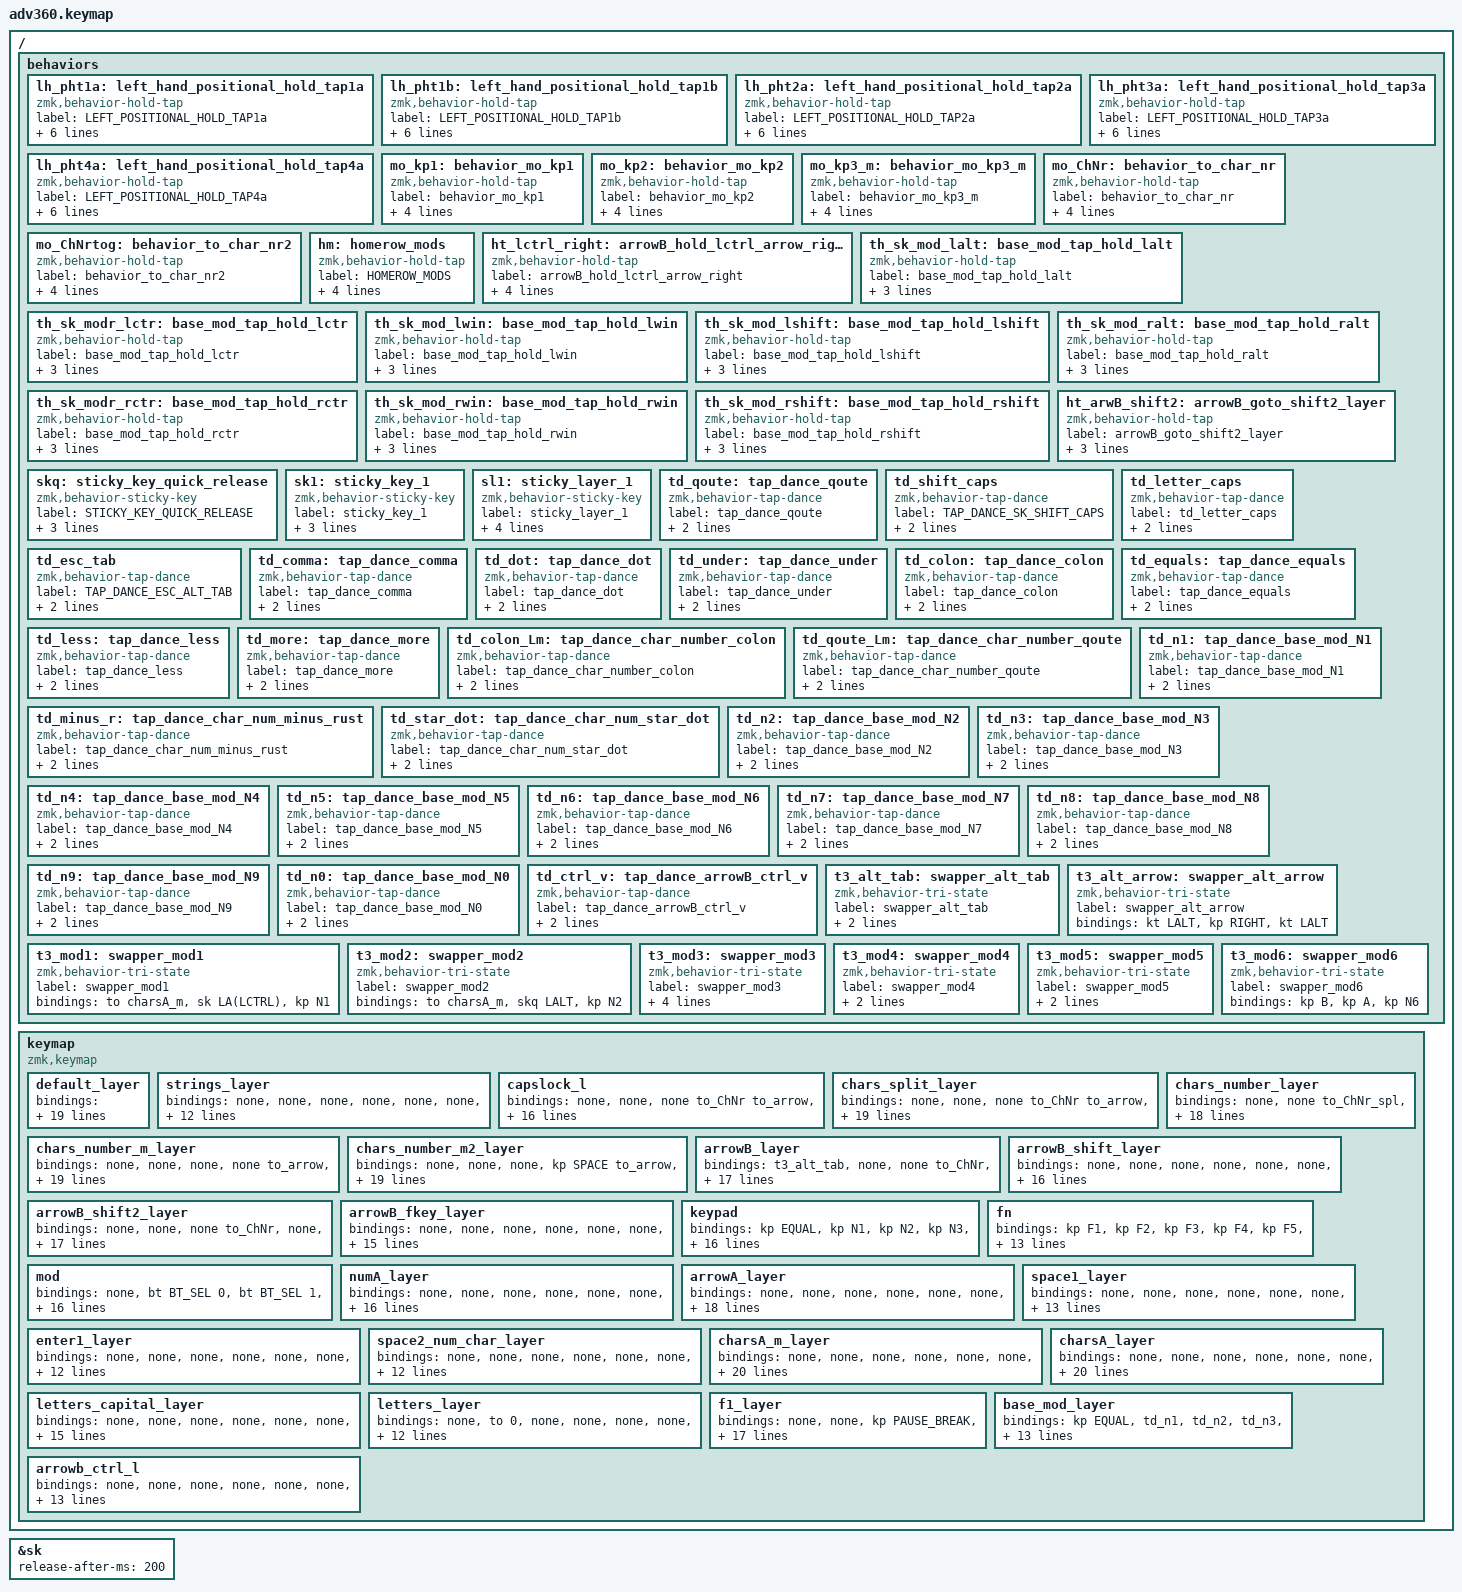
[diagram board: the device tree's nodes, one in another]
#include <behaviors.dtsi>
#include <dt-bindings/zmk/keys.h>
#include <dt-bindings/zmk/bt.h>
#include <dt-bindings/zmk/rgb.h>
#include <dt-bindings/zmk/backlight.h>

#define DEFAULT           0
#define strings_l         1
#define capslock_l          2
#define chars_split       3
#define chars_number      4
#define chars_number_m    5
#define chars_number_m2   6
#define arrowB            7
#define arrowB_shift      8  //|=
#define arrowB_shift2     9
#define arrowB_fkey       10

#define keypad_l          11 //default
#define fn_l              12 //default
#define mod_l             13 //default

#define numA              14
#define arrowA            15
#define space1            16
#define enter1            17
#define space2_num_char   18
#define charsA_m          19
#define charsA            20
#define letters_cap       21
#define letters           22
#define f1_layer          23
#define base_mod          24
#define arrowb_ctrl_l     25


//#define LSW LS(LWIN)

  &sk {
     release-after-ms = <200>;
 };

/ {
    behaviors {
      #include "macros.dtsi"

      lh_pht1a: left_hand_positional_hold_tap1a {
            compatible = "zmk,behavior-hold-tap";
            label = "LEFT_POSITIONAL_HOLD_TAP1a";
            #binding-cells = <2>;
  //          flavor = "tap-unless-interrupted";
            flavor = "tap-preferred";
            tapping-term-ms = <200>;                        // <---[[produces tap if held longer than tapping-term-ms]]
            quick-tap-ms = <200>;
            //global-quick-tap;
            bindings = <&kp>, <&kp>;
                                        //6              y               h                n
            hold-trigger-key-positions = <8 9 10 11 12   22 23 24 25 26  40 41 42 43 44   60 61 62 63 64>;    // 14 <---[[right-hand keys]]
      };

      lh_pht1b: left_hand_positional_hold_tap1b {
            compatible = "zmk,behavior-hold-tap";
            label = "LEFT_POSITIONAL_HOLD_TAP1b";
            #binding-cells = <2>;
   //         flavor = "tap-unless-interrupted";
            flavor = "tap-preferred";
            tapping-term-ms = <200>;                        // <---[[produces tap if held longer than tapping-term-ms]]
            quick-tap-ms = <200>;
            //global-quick-tap;
            bindings = <&kp>, <&kp>;
                                        //1              q               a                z
            hold-trigger-key-positions = <1 2 3 4 5      15 16 17 18 19  29 30 31 32 33   47 48 49 50 51>;    // 14 <---[[right-hand keys]]
      };


      lh_pht2a: left_hand_positional_hold_tap2a {
            compatible = "zmk,behavior-hold-tap";
            label = "LEFT_POSITIONAL_HOLD_TAP2a";
            #binding-cells = <2>;
            flavor = "tap-preferred";
            tapping-term-ms = <1000>;                        // <---[[produces tap if held longer than tapping-term-ms]]
            quick-tap-ms = <2000>;
            //global-quick-tap;
            bindings = <&kp>, <&kp>;
            hold-trigger-key-positions = <8 9 10 11 12   22 23 24 25 26  40 41 42 43 44   60 61 62 63 64>;    // 14 <---[[right-hand keys]]
      };

      lh_pht3a: left_hand_positional_hold_tap3a {
            compatible = "zmk,behavior-hold-tap";
            label = "LEFT_POSITIONAL_HOLD_TAP3a";
            #binding-cells = <2>;
            flavor = "balanced";
            tapping-term-ms = <1000>;                        // <---[[produces tap if held longer than tapping-term-ms]]
            quick-tap-ms = <2000>;
            //global-quick-tap;
            bindings = <&kp>, <&kp>;
            hold-trigger-key-positions = <8 9 10 11 12   22 23 24 25 26  40 41 42 43 44   60 61 62 63 64>;    // 14 <---[[right-hand keys]]
      };

      lh_pht4a: left_hand_positional_hold_tap4a {
            compatible = "zmk,behavior-hold-tap";
            label = "LEFT_POSITIONAL_HOLD_TAP4a";
            #binding-cells = <2>;
            flavor = "tap-unless-interrupted";
            tapping-term-ms = <400>;                        // <---[[produces tap if held longer than tapping-term-ms]]
            quick-tap-ms = <200>;
            //global-quick-tap;
            bindings = <&kp>, <&kp>;
            hold-trigger-key-positions = <8 9 10 11 12   22 23 24 25 26  40 41 42 43 44   60 61 62 63 64>;    // 14 <---[[right-hand keys]]
      };
// --------------------------------------------------------
    mo_kp1: behavior_mo_kp1 {
       label = "behavior_mo_kp1";
       compatible = "zmk,behavior-hold-tap";
       #binding-cells = <2>;
       flavor = "tap-preferred";
       tapping-term-ms = <200>;
       quick-tap-ms = <200>;
       bindings = <&mo>, <&kp>;
    };

    mo_kp2: behavior_mo_kp2 {
       label = "behavior_mo_kp2";
       compatible = "zmk,behavior-hold-tap";
       #binding-cells = <2>;
       flavor = "tap-preferred";
       tapping-term-ms = <200>;
       quick-tap-ms = <200>;
       bindings = <&mo>, <&kp>;
    }; 

    mo_kp3_m: behavior_mo_kp3_m {
       label = "behavior_mo_kp3_m";
       compatible = "zmk,behavior-hold-tap";
       #binding-cells = <2>;
       flavor = "tap-preferred";
       tapping-term-ms = <200>;
       quick-tap-ms = <200>;
       bindings = <&mo>, <&m_to0_space>;
    };

    mo_ChNr: behavior_to_char_nr {
       label = "behavior_to_char_nr";
       compatible = "zmk,behavior-hold-tap";
       #binding-cells = <2>;
       flavor = "tap-preferred";
       tapping-term-ms = <200>;
       quick-tap-ms = <200>;
       bindings = <&mo>, <&kp>;
    }; 

    mo_ChNrtog: behavior_to_char_nr2 {
       label = "behavior_to_char_nr2";
       compatible = "zmk,behavior-hold-tap";
       #binding-cells = <2>;
       flavor = "tap-preferred";
       tapping-term-ms = <200>;
       quick-tap-ms = <200>;
       bindings = <&tog>, <&kp>;
    }; 

// --------------------------------------------------------
      hm: homerow_mods {
          compatible = "zmk,behavior-hold-tap";
          label = "HOMEROW_MODS";
          #binding-cells = <2>;
          tapping-term-ms = <200>;
          quick_tap_ms = <175>;
          flavor = "tap-preferred";
          bindings = <&kp>, <&kp>;
      };

// --------------------------------------------------------
// TODO: ARROW_MODS
// not used

  ht_lctrl_right: arrowB_hold_lctrl_arrow_right {
            label = "arrowB_hold_lctrl_arrow_right";
            compatible = "zmk,behavior-hold-tap";
            #binding-cells = <2>;
            flavor = "tap-preferred";
            tapping-term-ms = <200>;                        // <---[[produces tap if held longer than tapping-term-ms]]
            quick-tap-ms = <200>;
            //global-quick-tap;
           // bindings = <&m_lctrl_right>, <&kp RIGHT>;       // TODO: ARROW_MODS
             bindings = <&mo>, <&kp>;
                                        //1              q               a                z
           // hold-trigger-key-positions = <1 2 3 4 5      15 16 17 18 19  29 30 31 32 33   47 48 49 50 51>;    // 14 <---[[right-hand keys]]
      };

// --------------------------------------------------------
// used for modifirs on base layer
// you still have the convenience of a sticky key, you don't have to keep pressing the key to activate it
// if you press it it activates the mod, and takes you to new layer where you can use top row for numbers

   th_sk_mod_lalt: base_mod_tap_hold_lalt {
            label = "base_mod_tap_hold_lalt";
            compatible = "zmk,behavior-hold-tap";
            #binding-cells = <2>;
            flavor = "hold-preferred";
            tapping-term-ms = <200>;
            bindings = <&m_0mod_lalt>, <&skq>;
        };

    th_sk_modr_lctr: base_mod_tap_hold_lctr {
            label = "base_mod_tap_hold_lctr";
            compatible = "zmk,behavior-hold-tap";
            #binding-cells = <2>;
            flavor = "hold-preferred";
            tapping-term-ms = <200>;
            bindings = <&m_0mod_lctr>, <&skq>;
        };

   th_sk_mod_lwin: base_mod_tap_hold_lwin {
            label = "base_mod_tap_hold_lwin";
            compatible = "zmk,behavior-hold-tap";
            #binding-cells = <2>;
            flavor = "hold-preferred";
            tapping-term-ms = <200>;
            bindings = <&m_0mod_lwin>, <&skq>;
        };

   th_sk_mod_lshift: base_mod_tap_hold_lshift {
            label = "base_mod_tap_hold_lshift";
            compatible = "zmk,behavior-hold-tap";
            #binding-cells = <2>;
            flavor = "hold-preferred";
            tapping-term-ms = <200>;
            bindings = <&m_0mod_lshift>, <&skq>;
        };

//------

   th_sk_mod_ralt: base_mod_tap_hold_ralt {
            label = "base_mod_tap_hold_ralt";
            compatible = "zmk,behavior-hold-tap";
            #binding-cells = <2>;
            flavor = "hold-preferred";
            tapping-term-ms = <200>;
            bindings = <&m_0mod_ralt>, <&skq>;
        };

    th_sk_modr_rctr: base_mod_tap_hold_rctr {
            label = "base_mod_tap_hold_rctr";
            compatible = "zmk,behavior-hold-tap";
            #binding-cells = <2>;
            flavor = "hold-preferred";
            tapping-term-ms = <200>;
            bindings = <&m_0mod_rctr>, <&skq>;
        };

   th_sk_mod_rwin: base_mod_tap_hold_rwin {
            label = "base_mod_tap_hold_rwin";
            compatible = "zmk,behavior-hold-tap";
            #binding-cells = <2>;
            flavor = "hold-preferred";
            tapping-term-ms = <200>;
            bindings = <&m_0mod_rwin>, <&skq>;
        };

   th_sk_mod_rshift: base_mod_tap_hold_rshift {
            label = "base_mod_tap_hold_rshift";
            compatible = "zmk,behavior-hold-tap";
            #binding-cells = <2>;
            flavor = "hold-preferred";
            tapping-term-ms = <200>;
            bindings = <&m_0mod_rshift>, <&skq>;
        };


// --------------------------------------------------------
// arrowB_layer
// 

   ht_arwB_shift2: arrowB_goto_shift2_layer {
            label = "arrowB_goto_shift2_layer";
            compatible = "zmk,behavior-hold-tap";
            #binding-cells = <2>;
            flavor = "hold-preferred";
            tapping-term-ms = <200>;
            bindings = <&mo>, <&to>;
        };

// --------------------------------------------------------


      skq: sticky_key_quick_release {
        compatible = "zmk,behavior-sticky-key";
        label = "STICKY_KEY_QUICK_RELEASE";
        #binding-cells = <1>;
        bindings = <&kp>;
        release-after-ms = <400>;
        quick-release;
      };

    sk1: sticky_key_1 {
        compatible = "zmk,behavior-sticky-key";
        label = "sticky_key_1";
        #binding-cells = <1>;
        release-after-ms = <1000>;
        bindings = <&kp>;
        ignore-modifiers;
    };

    sl1: sticky_layer_1 {
        compatible = "zmk,behavior-sticky-key";
        label = "sticky_layer_1";
        #binding-cells = <1>;
        release-after-ms = <1000>;
        bindings = <&mo>;
        ignore-modifiers;
        quick-release;
    };


// --------------------------------------------------------

   td_qoute: tap_dance_qoute {
            compatible = "zmk,behavior-tap-dance";
            label = "tap_dance_qoute";
            #binding-cells = <0>;
            tapping-term-ms = <200>;
            bindings = <&kp SINGLE_QUOTE>, <&kp DOUBLE_QUOTES>;
        };

   td_shift_caps: td_shift_caps {
            compatible = "zmk,behavior-tap-dance";
            label = "TAP_DANCE_SK_SHIFT_CAPS";
            #binding-cells = <0>;
            tapping-term-ms = <200>;
            bindings = <&skq LSHFT>, <&to capslock_l>;
      };

   td_letter_caps: td_letter_caps {
            compatible = "zmk,behavior-tap-dance";
            label = "td_letter_caps";
            #binding-cells = <0>;
            tapping-term-ms = <200>;
            bindings = <&sl letters_cap>, <&to capslock_l>;
      };

      td_esc_tab: td_esc_tab {
            compatible = "zmk,behavior-tap-dance";
            label = "TAP_DANCE_ESC_ALT_TAB";
            #binding-cells = <0>;
            tapping-term-ms = <200>;
            bindings = <&kp ESC>, <&kp LA(TAB)>;
      };

     td_comma: tap_dance_comma {
            compatible = "zmk,behavior-tap-dance";
            label = "tap_dance_comma";
            #binding-cells = <0>;
            tapping-term-ms = <200>;
            bindings = <&kp COMMA>, <&kp LESS_THAN>;
        };
 
    td_dot: tap_dance_dot {
            compatible = "zmk,behavior-tap-dance";
            label = "tap_dance_dot";
            #binding-cells = <0>;
            tapping-term-ms = <200>;
            bindings = <&kp DOT>, <&kp GREATER_THAN>;
        };

    td_under: tap_dance_under {
            compatible = "zmk,behavior-tap-dance";
            label = "tap_dance_under";
            #binding-cells = <0>;
            tapping-term-ms = <200>;
            bindings = <&kp UNDER>, <&kp QMARK>;
        }; 

    td_colon: tap_dance_colon {
            compatible = "zmk,behavior-tap-dance";
            label = "tap_dance_colon";
            #binding-cells = <0>;
            tapping-term-ms = <200>;
            bindings = <&kp SEMI>, <&kp COLON>;
        }; 

// -----------
// use on chars_number_m_layer

    td_equals: tap_dance_equals {
            compatible = "zmk,behavior-tap-dance";
            label = "tap_dance_equals";
            #binding-cells = <0>;
            tapping-term-ms = <200>;
            bindings = <&m_toNrCh_equal>, <&m_toNrCh_equal2>;
        }; 

    td_less: tap_dance_less {
            compatible = "zmk,behavior-tap-dance";
            label = "tap_dance_less";
            #binding-cells = <0>;
            tapping-term-ms = <200>;
            bindings = <&m_toNrCh_less>, <&m_toNrCh_less2>;
        }; 

    td_more: tap_dance_more {
            compatible = "zmk,behavior-tap-dance";
            label = "tap_dance_more";
            #binding-cells = <0>;
            tapping-term-ms = <200>;
            bindings = <&m_toNrCh_more>, <&m_toNrCh_more2>;
        }; 


    td_colon_Lm: tap_dance_char_number_colon {
            label = "tap_dance_char_number_colon";
            compatible = "zmk,behavior-tap-dance";
            #binding-cells = <0>;
            tapping-term-ms = <200>;
            bindings = <&m_toNrCh_colon>, <&m_toNrCh_colon2>;
        }; 

td_qoute_Lm: tap_dance_char_number_qoute {
            label = "tap_dance_char_number_qoute";
            compatible = "zmk,behavior-tap-dance";
            #binding-cells = <0>;
            tapping-term-ms = <200>;
            bindings = <&m_toNrCh_qoute>, <&m_toNrCh_qoute2>;
        }; 

    td_minus_r: tap_dance_char_num_minus_rust {
            label = "tap_dance_char_num_minus_rust";
            compatible = "zmk,behavior-tap-dance";
            #binding-cells = <0>;
            tapping-term-ms = <200>;
            bindings = <&m_toNrCh_minus>, <&m_toNrCh_r_minus>;
        }; 

    td_star_dot: tap_dance_char_num_star_dot {
            label = "tap_dance_char_num_star_dot";
            compatible = "zmk,behavior-tap-dance";
            #binding-cells = <0>;
            tapping-term-ms = <200>;
            bindings = <&m_toNrCh_star>, <&m_toNrCh_star2>;
        }; 


// --------------------------------------------------------

   td_n1: tap_dance_base_mod_N1 {
            label = "tap_dance_base_mod_N1";
            compatible = "zmk,behavior-tap-dance";
            #binding-cells = <0>;
            tapping-term-ms = <200>;
            bindings = <&kp N1>, <&kp N6>;
        };

   td_n2: tap_dance_base_mod_N2 {
            label = "tap_dance_base_mod_N2";
            compatible = "zmk,behavior-tap-dance";
            #binding-cells = <0>;
            tapping-term-ms = <200>;
            bindings = <&kp N2>, <&kp N7>;
        };

   td_n3: tap_dance_base_mod_N3 {
            label = "tap_dance_base_mod_N3";
            compatible = "zmk,behavior-tap-dance";
            #binding-cells = <0>;
            tapping-term-ms = <200>;
            bindings = <&kp N3>, <&kp N8>;
        };

   td_n4: tap_dance_base_mod_N4 {
            label = "tap_dance_base_mod_N4";
            compatible = "zmk,behavior-tap-dance";
            #binding-cells = <0>;
            tapping-term-ms = <200>;
            bindings = <&kp N4>, <&kp N9>;
        };

   td_n5: tap_dance_base_mod_N5 {
            label = "tap_dance_base_mod_N5";
            compatible = "zmk,behavior-tap-dance";
            #binding-cells = <0>;
            tapping-term-ms = <200>;
            bindings = <&kp N5>, <&kp N0>;
        };

   td_n6: tap_dance_base_mod_N6 {
            label = "tap_dance_base_mod_N6";
            compatible = "zmk,behavior-tap-dance";
            #binding-cells = <0>;
            tapping-term-ms = <200>;
            bindings = <&kp N6>, <&kp N1>;
        };

   td_n7: tap_dance_base_mod_N7 {
            label = "tap_dance_base_mod_N7";
            compatible = "zmk,behavior-tap-dance";
            #binding-cells = <0>;
            tapping-term-ms = <200>;
            bindings = <&kp N7>, <&kp N2>;
        };

   td_n8: tap_dance_base_mod_N8 {
            label = "tap_dance_base_mod_N8";
            compatible = "zmk,behavior-tap-dance";
            #binding-cells = <0>;
            tapping-term-ms = <200>;
            bindings = <&kp N8>, <&kp N3>;
        };

   td_n9: tap_dance_base_mod_N9 {
            label = "tap_dance_base_mod_N9";
            compatible = "zmk,behavior-tap-dance";
            #binding-cells = <0>;
            tapping-term-ms = <200>;
            bindings = <&kp N9>, <&kp N4>;
        };

   td_n0: tap_dance_base_mod_N0 {
            label = "tap_dance_base_mod_N0";
            compatible = "zmk,behavior-tap-dance";
            #binding-cells = <0>;
            tapping-term-ms = <200>;
            bindings = <&kp N0>, <&kp N5>;
        };

// --------------------------------------------------------
// used on arrowB_layer

   td_ctrl_v: tap_dance_arrowB_ctrl_v {
            label = "tap_dance_arrowB_ctrl_v";
            compatible = "zmk,behavior-tap-dance";
            #binding-cells = <0>;
            tapping-term-ms = <200>;
            bindings = <&kp LC(V)>, <&a_ctrl_v_enter>;
        };

// --------------------------------------------------------

// window switching in windows
  t3_alt_tab: swapper_alt_tab {
            compatible = "zmk,behavior-tri-state";
            label = "swapper_alt_tab";
            #binding-cells = <0>;
            bindings = <&kt LALT>, <&kp TAB>, <&kt LALT>;
            ignored-key-positions = <46 65>;  // left shfit and right shift
        };

// you can use this to move the currsor forward and using a single key only
// its kind of similar how the sticky key works, as long as you keep pressing it
// it will output the alt+arrow key and it is disabled by any other key
// "smart" key combination

  t3_alt_arrow: swapper_alt_arrow {
            label = "swapper_alt_arrow";
            compatible = "zmk,behavior-tri-state";
            #binding-cells = <0>;
            bindings = <&kt LALT>, <&kp RIGHT>, <&kt LALT>;
           // ignored-key-positions = <46 65>;  // left shfit and right shift
        };

  t3_mod1: swapper_mod1 {
            label = "swapper_mod1";
            compatible = "zmk,behavior-tri-state";
            #binding-cells = <0>;
            bindings = <&to charsA_m>, <&sk LA(LCTRL)>, <&kp N1>;
           // ignored-key-positions = <46 65>;  // left shfit and right shift
        };

  t3_mod2: swapper_mod2 {
            label = "swapper_mod2";
            compatible = "zmk,behavior-tri-state";
            #binding-cells = <0>;
            bindings = <&to charsA_m>, <&skq LALT>, <&kp N2>;
           // ignored-key-positions = <46 65>;  // left shfit and right shift
        };

  t3_mod3: swapper_mod3 {
            label = "swapper_mod3";
            compatible = "zmk,behavior-tri-state";
            #binding-cells = <0>;
            bindings = <&to charsA>, <&sk LA(LSHFT)>, <&kp N3>;
            ignored-key-positions = <8 9 10 11 12   22 23 24 25 26  40 41 42 43 44   60 61 62 63 64>;
            ignored-layers = <0 charsA_m charsA>;
        };

  t3_mod4: swapper_mod4 {
            label = "swapper_mod4";
            compatible = "zmk,behavior-tri-state";
            #binding-cells = <0>;
            //bindings = <&skq LALT>, <&sl charsA>, <&kp N4>;         //this combination doesn't work;
            bindings = <&none>, <&sl charsA>, <&sk LA(LSHFT)>;
           // ignored-key-positions = <46 65>;  
            ignored-layers = <charsA>;
        };

  t3_mod5: swapper_mod5 {
            label = "swapper_mod5";
            compatible = "zmk,behavior-tri-state";
            #binding-cells = <0>;
            bindings = <&to charsA>, <&kp A>, <&kp N5>;
           // ignored-key-positions = <46 65>;  // left shfit and right shift
            ignored-layers = <charsA>;
        };

    t3_mod6: swapper_mod6 {
            label = "swapper_mod6";
            compatible = "zmk,behavior-tri-state";
            #binding-cells = <0>;
            bindings = <&kp B>, <&kp A>, <&kp N6>;
           // ignored-key-positions = <46 65>;  // left shfit and right shift
        };


// --------------------------------------------------------


};



  keymap {
    compatible = "zmk,keymap";

//    #define hr_A &lh_pht1 LSFT A
//    #define hr_S &lh_pht2 LWIN S
//    #define hr_D &lh_pht3 LCTRL D
 //   #define hr_F &lh_pht4 LALT F

 //   #define hr_A &lh_pht1 LSFT A
 //   #define hr_S &lh_pht2 LSFT S
 //   #define hr_D &lh_pht3 LSFT D
 //   #define hr_F &lh_pht4 LSFT F

#define hr_A &lh_pht1a LSFT A
#define hr_S &lh_pht1a LSFT S
#define hr_D &lh_pht1a LSFT D
//#define hr_F &lh_pht1a LSFT F

#define hr_N1 &lh_pht1a LSFT N1
#define hr_N2 &lh_pht1a LSFT N2
#define hr_N3 &lh_pht1a LSFT N3
#define hr_N4 &lh_pht1a LSFT N4
#define hr_N5 &lh_pht1a LSFT N5

#define hr_Q &lh_pht1a LSFT Q
#define hr_W &lh_pht1a LSFT W
//#define hr_E &lh_pht1a LSFT E
#define hr_R &lh_pht1a LSFT R
#define hr_T &lh_pht1a LSFT T

#define hr_G &lh_pht1a LSFT G
#define hr_Z &lh_pht1a LSFT Z
#define hr_X &lh_pht1a LSFT X
#define hr_C &lh_pht1a LSFT C
#define hr_V &lh_pht1a LSFT V
#define hr_B &lh_pht1a LSFT B

 // ------

#define hr_Y &lh_pht1b LSFT Y
#define hr_U &lh_pht1b LSFT U
//#define hr_I &lh_pht1b LSFT I
#define hr_O &lh_pht1b LSFT O
#define hr_P &lh_pht1b LSFT P

#define hr_H &lh_pht1b LSFT H
#define hr_J &lh_pht1b LSFT J
#define hr_K &lh_pht1b LSFT K
//#define hr_L &lh_pht1b LSFT L
#define hr_COLON  &lh_pht1b LSFT COLON

#define hr_N6 &lh_pht1b LSFT N6
#define hr_N7 &lh_pht1b LSFT N7
//#define hr_N8 &lh_pht1b LSFT N8
#define hr_N9 &lh_pht1b LSFT N9
#define hr_N0 &lh_pht1b LSFT N0

#define hr_N &lh_pht1b LSFT N
#define hr_M &lh_pht1b LSFT M
#define hr_COMMA &lh_pht1b LSFT COMMA
#define hr_DOT &lh_pht1b LSFT DOT
//#define hr_FSLH &lh_pht1b LSFT FSLH
#define hr_UNDER &lh_pht1b LSFT UNDER

#define mo_SPACE &mo_kp1 space1 SPACE
#define mo_ENTER &mo_kp1 enter1 ENTER

//on the char_num layer allows to press enter and move to L0
#define mo_SPACE2   &mo_kp1   space2_num_char SPACE
// macron on tap, on hold enable new layer
// allows to tap and change layer, on hold on the new layer you can change layer as well
#define mo_SPACE3_m &mo_kp3_m space2_num_char 0


//#define mo_FF1 &mo_kp2 charsA F
//#define mo_FF2 &mo_kp2 arrowA F
//#define mo_FF2 &mo_kp2 arrowB_shift2 F
#define mo_FF2 &mo_kp2 arrowB_fkey F

//#define mo_N4 &mo_kp2 arrowA N4
#define mo_N4 &mo_kp2 arrowB_fkey N4

//string shortcuts
#define mo_E &mo_kp2 strings_l E
#define mo_I &mo_kp2 strings_l I


//#define mo_DD &mo_kp2 charsA D    
#define   mo_DD &mo_ChNr     chars_number_m D  
//#define mo_KK &mo_kp2 numA K
#define   mo_KK &mo_ChNr     chars_number_m K     


//#define mo_SS &mo_ChNrtog  chars_number_m S
#define   mo_SS &mo_ChNr     chars_number_m2 S
#define   mo_LL &mo_ChNr     chars_number_m2 L


//allows to type: \n or \d
// space, enter + alt combination
#define mo_N5    &mo_ChNr     chars_number_m N5
#define mo_SLASH &mo_ChNr     chars_number_m SLASH

// space, enter + ctrl combination
#define mo_N6    &mo_ChNr     chars_number_m2 N6
#define mo_PLUS  &mo_ChNr     chars_number_m2 PLUS


#define to_arrow &to arrowB 

#define to_ChNr     &to chars_number 
#define to_ChNr_spl &to chars_split 



// --------------------------------------------------------

#define _lalt  &th_sk_mod_lalt 0 LALT 
#define _lctr  &th_sk_modr_lctr 0 LCTRL
#define _lwin  &th_sk_mod_lwin 0 LWIN
#define _lsft  &th_sk_mod_lshift 0 LSHFT 

#define _ralt  &th_sk_mod_ralt 0 RALT 
#define _rctr  &th_sk_modr_rctr 0 RCTRL
#define _rwin  &th_sk_mod_rwin 0 RWIN
#define _rsft  &th_sk_mod_rshift 0 RSHFT 

// --------------------------------------------------------

#define go_arrowB_shift2 &ht_arwB_shift2 arrowB_shift2 arrowB_shift2

// --------------------------------------------------------

    default_layer {
      bindings = <
       &t3_alt_tab  hr_N1     to_ChNr_spl to_ChNr   to_arrow    hr_N5  &tog keypad_l                                                                                   &mo mod_l   hr_N6  hr_N7       to_ChNr    to_ChNr_spl hr_N0      &kp BSPC
       &td_esc_tab  hr_Q       hr_W       mo_E      hr_R        hr_T   &t3_alt_arrow                                                                                   &none       hr_Y   hr_U         mo_I       hr_O       hr_P       &kp DEL
       &kp  TAB     hr_A       mo_SS      mo_DD     mo_FF2      hr_G   &kp LC(RIGHT)               &kp ENTER  &bootloader                &bootloader  &kp Z            &none       hr_H   hr_J         mo_KK      mo_LL      hr_COLON   &kp DOUBLE_QUOTES
    &td_shift_caps  hr_Z       hr_X       hr_C      hr_V        hr_B                    &none      &none      &kp BSPC    &none   &none  &kp PG_UP &none     &none                 hr_N   hr_M         hr_COMMA   hr_DOT     hr_UNDER   _rsft
       &mo  2       _lwin      _lctr      _lalt     &sl arrowA                        mo_SPACE   &sl charsA   &kp DEL                    &kp PG_DN &sl numA  mo_ENTER                     &sl f1_layer _ralt      _rctr      _rwin      &mo 2
      >; 
    };

// h  : https://
// d  : doesn't
// c  : can't 

    strings_layer {
      bindings = <
        &none &none        &none        &none        &none        &none        &none                                                                              &none      &none        &none        &none        &none        &none        &none
        &none &to 0        &none        &none        &none        &none        &none                                                                              &none      &none        &none        &none        &none        &none        &none
        &none &none        &m_s_self    &m_d_doesnt  &none        &none        &none            &none  &none                        &none   &kp S                 &none      &m_h_https   &none        &none        &none        &none        &none
        &none &none        &none        &m_c_cant    &none        &none                 &none   &none  &none  &none         &none   &none   &none  &none                     &none        &none        &none        &none        &none        &none
        &none &none        &none        &none        &none                              &none   &none  &none                        &none   &none  &none                                  &none        &none        &none        &none        &none
      >;
    };

    capslock_l {
      bindings = <
        &none &none        &none        to_ChNr      to_arrow     &none        &none                                                                               &none      &none        &none        to_ChNr_spl   &none        &none           &kp BSPC
        &none &kp LS(Q)    &kp LS(W)    &kp LS(E)    &kp LS(R)    &kp LS(T)    &none                                                                               &none      &kp LS(Y)    &kp LS(U)    &kp LS(I)     &kp LS(O)    &kp LS(P)       &kp DEL
      &kp TAB &kp LS(A)    &kp LS(S)    &kp LS(D)    &kp LS(F)    &kp LS(G)    &none               &none       &none                        &none    &kp U         &none      &kp LS(H)    &kp LS(J)    &kp LS(K)     &kp LS(L)    &kp COLON       &kp DOUBLE_QUOTES
        &to 0 &kp LS(Z)    &kp LS(X)    &kp LS(C)    &kp LS(V)    &kp LS(B)             &none      &none       &none  &none         &none   &none    &none  &none             &kp LS(N)    &kp LS(M)    &kp COMMA     &kp DOT      &kp UNDER       &none
        &none &none        &none        &none        mo_SPACE2                         mo_SPACE3_m &sl charsA  &none                &none   &sl numA &m_to0_enter             &kp ENTER    &none         &none        &none           &none
      >;
    };

// &m_to0_space

// chars are on the left and right half
// the hard to reach chars from the left has been moved to right
// some combination so chars should be easier to type right now
// the righ side keys are kept "fixed" of what we already use, so you only have to learn the keys on the left
//
// - Lshift on double tap enables capslock layer
// - moved double_qoutes to index finger to make it easy to type: { "%p" }
// layer used to type "wired" char sequences that are "unergonomic" otherwise
// \= @tile
// "#{@item.type}
// - typing '.*' requires right hand to jump from the bottom to top row; added the '*' char in the "alt" key spot

    chars_split_layer {
      bindings = <
        &none            &none       &none          to_ChNr           to_arrow       &none             &none                                                                               &none       &none      &none            to_ChNr       &none     &none       &kp BSPC
        &none            &kp QMARK   &kp GRAVE      &kp BACKSLASH     &kp PERCENT    &kp RIGHT_BRACKET &none                                                                               &none       &kp AT     &kp LEFT_BRACKET &kp MINUS     &kp EQUAL &kp EXCL    &kp DEL
        &kp SINGLE_QUOTE &kp STAR    &kp AMPERSAND  &kp TILDE         &kp LEFT_BRACE &kp RIGHT_BRACE   &sl letters         &kp ENTER    &none                 &none  &kp T                 &sl letters &kp DOLLAR &kp LPAR         mo_SLASH      mo_PLUS   &kp COLON   &kp DOUBLE_QUOTES
        &to capslock_l   &kp SEMI    &kp LESS_THAN  &kp GREATER_THAN  &kp CARET      &kp RPAR                      &none   &none        &none  &none  &none   &none  &none   &none                     &kp PIPE   &kp HASH         &kp COMMA     &kp DOT   &kp UNDER   &none
        &none            &none       &none          &kp LC(RIGHT)     &sl arrowA                                 mo_SPACE2 &m_to0_space &none                 &kp DEL &to 0  &m_to0_enter                         &none            &kp LC(RIGHT) &none     &none       &none 
      >;
    };  

   chars_number_layer {
      bindings = <
        &none            &none             to_ChNr_spl       &kp SPACE         to_arrow          &none         &none                                                                              &kp CARET &kp PERCENT &kp LEFT_BRACE   &kp STAR          &kp AMPERSAND    &kp RIGHT_BRACE &kp BSPC
        &none            &to 0             &kp N9            &kp N8            &kp N7            &none         &none                                                                              &none     &kp AT      &kp LEFT_BRACKET &kp MINUS         &kp EQUAL        &kp EXCL        &kp GRAVE
        &kp TAB          &to 0             mo_N6             mo_N5             mo_N4             &kp N0        &sl letters         &kp ENTER   &none                 &none   &kp E              &sl letters &kp DOLLAR  &kp LPAR         mo_SLASH          mo_PLUS          &td_colon       &td_qoute
        &td_letter_caps  &kp LC(RIGHT)     &kp N3            &kp N2            &kp N1            &key_repeat             &none     &none       &none  &none  &none   &none   &none    &none                 &kp PIPE    &kp HASH         &td_comma         &td_dot          &td_under       &sl letters_cap
        &none            &none             &none             &none             &sl arrowA                           mo_SPACE2     &m_to0_space &none              &kp DEL &sl letters &m_to0_enter                      &kp RPAR         &kp RIGHT_BRACKET &none            &kp TILDE       &kp BACKSLASH
      >;
    };  

//on default layer use to type:
// ' / ' or ' + ' or '<end>;<enter>' or ' == ' or \n or \d or ' > ' or ' >= ' ... 
// if macro is used often it changes to chars_number layer to contine
// -  : ' - '<new_layer>| 
// -- : ' -> |'
// spc: 'alt+right space|'
// '  : '''
// "  : """
// t  : \t 
// x  : <|>
// space: alt+right, space, L_Nr
// enter: alt+right, space, L_0
// *    : .*, L_Nr
//
//TODO:
//  '<end> ', example: "string|" -> "string" |

   chars_number_m_layer {
      bindings = <
        &none            &none             &none             &none             to_arrow          &none         &none                                                                              &kp CARET   &kp PERCENT &kp LEFT_BRACE   &td_star_dot      &kp AMPERSAND    &kp RIGHT_BRACE &kp BSPC
        &none            &to 0             &m_N9             &m_N8             &m_N7             &m_toNrCh_t &none                                                                                &none       &kp AT      &kp LEFT_BRACKET &td_minus_r       &td_equals       &kp EXCL        &kp GRAVE
        &key_repeat      &to 0             &m_N6             &m_N5_d           &m_N4             &m_N0         &sl letters         &kp ENTER   &none                 &none   &kp M                &sl letters &kp DOLLAR  &m_toNrCh_lpar   &m_toNrCh_slash   &m_toNrCh_plus   &td_colon_Lm    &td_qoute_Lm
        &sl letters_cap  &m_N2            &m_toNrCh_diamond  &m_N2             &m_N1             &kp DOT                 &none     &none       &none  &none  &none   &none   &none    &none                &m_toNrCh_pipe &kp HASH         &td_less          &td_more         &td_under       &sl letters_cap
        &none            &none             &none             &none             &sl arrowA                        &m_toNrCh_space   &sl letters &none              &kp DEL &sl letters &m_toNrCh_enter_space               &kp RPAR         &kp RIGHT_BRACKET &none            &kp TILDE       &kp BACKSLASH
      >;
    };

//on base layer helps to type the chars sequnce that requries movements like: ^\
// LS \^ or \% or in general \<char> or ^<char>
// space: ctrl+right, space, L_Nr
// enter: ctrl+right, space, L0
// 

   chars_number_m2_layer {
      bindings = <
        &none            &none             &none             &kp SPACE         to_arrow          &none         &none                                                                              &kp CARET &kp PERCENT &kp LEFT_BRACE   &kp STAR          &kp AMPERSAND    &kp RIGHT_BRACE &kp BSPC
        &none            &to 0             &kp N9            &kp N8            &kp N7            &kp LC(RIGHT) &none                                                                              &none     &kp AT      &kp LEFT_BRACKET &kp MINUS         &kp EQUAL        &kp EXCL        &kp GRAVE
        &kp TAB          &to 0             &none             &kp BACKSLASH     &kp CARET         &kp N0        &sl letters         &kp ENTER   &none                 &none   &kp R              &sl letters &kp DOLLAR  &kp LPAR         &kp SLASH         &kp PLUS         &td_colon       &td_qoute
        &sl letters_cap  &kp COMMA         &kp N3            &kp N2            &kp N1            &key_repeat             &none     &none       &none  &none  &none   &none   &none    &none                 &kp PIPE    &kp HASH         &m_comma_c        &td_dot          &td_under       &sl letters_cap
        &none            &none             &none             &none             &sl arrowA                     &m_toNrCh_space_c    &sl letters &none                 &kp DEL &sl letters &m_toNrCh_enter_space_c        &kp RPAR         &kp RIGHT_BRACKET &none            &kp TILDE       &kp BACKSLASH
      >;
    }; 

  // TODO: ARROW_MODS

  #define _ctrl_right  &ht_lctrl_right arrowb_ctrl_l RIGHT 

    arrowB_layer { 
      bindings = <
  &t3_alt_tab   &none     &none         to_ChNr        &none              &none        &none                                                                              &none      &none        &none            &none        &none         &none        &kp BSPC
    &td_esc_tab &to 0     &none         &none          &none              &none        &none                                                                              &none      &kp LA(HOME) &kp LA(LEFT)     &kp UP       &kp LA(RIGHT) &kp LA(END)  &kp DEL
        &kp TAB &to 0     &none         &sk LA(LCTRL)  go_arrowB_shift2   &none        &sl letters       &kp ENTER   &none                        &none   &kp A          &sl letters &kp HOME     &kp LEFT         &kp DOWN     _ctrl_right   &kp END      &kp PG_UP
        &kp INS &kp LC(Z) &kp LC(X)     &kp LC(C)      &td_ctrl_v         &key_repeat           &none    &none       &kp BSPC  &none      &none   &none   &none  &none               &kp LC(HOME) &kp LC(LEFT)     &none        &kp LC(RIGHT) &kp LC(END)  &kp PG_DN
        &none   &kp LC(Y) &none         &none          &sl arrowA                               mo_SPACE &sl charsA  &kp DEL              &none   &sl numA &kp ENTER                              &sl f1_layer     &none        &none         &none        &none
      >;
    };
 
    //not used
    arrowB_shift_layer { 
      bindings = <
        &none   &none        &none        &none      &none         &none        &none                                                                              &none      &none        &none            &none        &none         &none        &kp BSPC
        &kp ESC &a_to0       &kt LSHFT    &a_shift_up &none        &none        &none                                                                              &none      &kp LA(HOME) &kp LA(LEFT)     &kp UP       &kp LA(RIGHT) &kp LA(END)  &kp DEL
        &kp TAB &kp N2       &none        &sk LSHFT  &sk LA(LCTRL) &sl numA     &none             &kp ENTER   &none                        &none   &kp B           &none      &kp HOME     &kp LEFT         &kp DOWN     &kp RIGHT     &kp END      &kp PG_UP
        &kp INS &a_ctrl_z    &a_ctrl_x    &a_ctrl_c  &a_ctrl_v     &none                &none     &none       &none  &none         &none   &none   &none  &none               &kp LC(HOME) &kp LC(LEFT)     &none        &kp LC(RIGHT) &kp LC(END)  &kp PG_DN
        &none   &kp LC(Y)    &none        &none      &tog arrowA                        &kp SPACE &to charsA  &none                &none   &to numA &kp ENTER                              &to f1_layer     &none        &none         &none        &none
      >;
    }; 

    arrowB_shift2_layer {
      bindings = <
        &none   &none        &none        to_ChNr    &none         &none        &none                                                                              &none      &none        &none            &none        &none             &none        &kp BSPC
        &kp ESC &to 0        &none        &to arrowB &none         &none        &none                                                                              &none      &kp LA(HOME) &kp LS(LA(LEFT)) &kp LS(UP)   &kp LS(LA(RIGHT)) &kp LA(END)  &kp DEL
        &kp TAB &to 0        &none     &sk LA(LCTRL) &to arrowB    &none        &none             &none       &none                        &none   &kp N           &none      &kp LS(HOME) &kp LS(LEFT)     &kp LS(DOWN) &kp LS(RIGHT)     &kp LS(END)  &kp LS(PG_UP)
        &kp INS &b_ctrl_z    &b_ctrl_x    &b_ctrl_c  &b_ctrl_v     &none                 &none    &none       &none  &none         &none   &none   &none  &none               &kp LC(HOME) &kp LS(LC(LEFT)) &none        &kp LS(LC(RIGHT)) &kp LC(END)  &kp LS(PG_DN)
        &none   &kp LC(Y)    &none        &none      &sl arrowA                        &kp SPACE &to charsA  &none                &none   &to numA &kp ENTER                              &sl f1_layer     &none        &none             &none        &none
      >;
    };

// used from base layer on hold
    arrowB_fkey_layer {
      bindings = <
        &none   &none        &none        &none      &none         &none        &none                                                                              &none      &none        &none            &none        &none             &none        &kp BSPC
        &kp ESC &to 0        &none        &none      &none         &none        &none                                                                              &none      &kp LA(HOME) &kp LS(LA(LEFT)) &kp UP   &kp LS(LA(RIGHT)) &kp LA(END)  &kp DEL
        &kp TAB &none        &sk LSHFT &sk LA(LCTRL) &none         &none        &none             &none       &none                        &none   &kp C           &none      &kp LS(HOME) &kp LEFT         &kp DOWN     &kp RIGHT         &kp LS(END)  &kp PG_UP
        &kp INS &none        &none        &none      &none         &none                 &none    &none       &none  &none         &none   &none   &none  &none               &kp LC(HOME) &kp LA(LEFT)     &none        &kp LA(RIGHT)     &kp LC(END)  &kp PG_DN
        &none   &none        &none        &none      &none                              &kp SPACE &to charsA  &none                &none   &to numA &kp ENTER                              &to f1_layer     &none        &none             &none        &none
      >;
    }; 

    keypad {
      bindings = <
        &kp EQUAL &kp N1    &kp N2   &kp N3   &kp N4     &kp N5 &trans                                                                       &mo 3 &kp N6 &kp KP_NUM &kp KP_EQUAL &kp KP_DIVIDE &kp KP_MULTIPLY &kp MINUS
        &kp TAB   &to 0     &kp W    &kp E    &kp R      &kp T  &none                                                                        &none &kp Y  &kp KP_N7  &kp KP_N8    &kp KP_N9     &kp KP_MINUS    &kp BSLH
        &kp ESC   &kp A     &kp S    &kp D    &kp F      &kp G  &none           &kp LCTRL &kp LALT             &kp LGUI  &kp D               &none &kp H  &kp KP_N4  &kp KP_N5    &kp KP_N6     &kp KP_PLUS     &kp SQT
        &kp LSHFT &kp Z     &kp X    &kp C    &kp V      &kp B         &none    &none     &kp HOME &none &none &kp PG_UP &none     &none           &kp N  &kp KP_N1  &kp KP_N2    &kp KP_N3     &kp KP_ENTER    &kp RSHFT
        &mo 2     &kp GRAVE &kp CAPS &kp LEFT &kp RIGHT                &kp BSPC &kp DEL   &kp END              &kp PG_DN &kp ENTER &kp KP_N0              &kp UP     &kp DOWN     &kp KP_DOT    &kp RBKT        &mo 2
      >;
    };

    fn {
      bindings = <
        &kp F1 &kp F2 &kp F3 &kp F4 &kp F5 &kp F6 &tog 1                                                       &mo 3 &kp F7 &kp F8 &kp F9 &kp F10 &kp F11 &kp F12
        &trans &to 0  &trans &trans &trans &trans  &none                                                       &none &trans &trans &trans &trans  &trans  &trans
        &trans &trans &trans &trans &trans &trans  &none        &trans &trans             &trans &trans        &none &trans &trans &trans &trans  &trans  &trans
        &trans &trans &trans &trans &trans &trans        &none  &none  &trans &none &none &trans &none  &none        &trans &trans &trans &trans  &trans  &trans
        &trans &trans &trans &trans &trans               &trans &trans &trans             &trans &trans &trans              &trans &trans &trans  &trans  &trans
      >;
    };  

    mod {
      bindings = <
        &none &bt BT_SEL 0 &bt BT_SEL 1 &bt BT_SEL 2 &bt BT_SEL 3 &bt BT_SEL 4 &none                                                                                                          &trans                 &bt BT_SEL 0 &bt BT_SEL 1 &bt BT_SEL 2 &bt BT_SEL 3 &bt BT_SEL 4 &none
        &none &to 0        &none        &none        &none        &none        &bootloader                                                                                                    &bootloader            &none        &none        &none        &none        &none        &none
        &none &none        &none        &none        &none        &none        &rgb_ug RGB_MEFS_CMD 5                 &bt BT_CLR &bt BT_CLR             &bt BT_CLR &bt BT_CLR                 &rgb_ug RGB_MEFS_CMD 5 &none        &none        &none        &none        &none        &none
        &none &none        &none        &none        &none        &none                               &none           &none      &none      &none &none &none      &none      &none                                  &none        &none        &none        &none        &none        &none
        &none &none        &none        &bl BL_INC   &bl BL_DEC                                       &rgb_ug RGB_TOG &bl BL_TOG &none                  &none      &bl BL_TOG &rgb_ug RGB_TOG                                     &bl BL_INC   &bl BL_DEC   &none        &none        &none
      >;
    };

  numA_layer {
      bindings = <
        &none    &none        &none        &none        &none        &none        &none                                                                                  &none      &none                  &none             &none             &none             &none             &none
        &none    &to 0        &kp N9       &kp N8       &kp N7       &kp LC(RIGHT) &none                                                                                 &none      &none                  &none             &sk LC(LG(LSHFT)) &sk LA(LG(LSHFT)) &sk LA(LC(LSHFT)) &none
        &none    &kp UNDER    &kp N6       &kp N5       &kp N4       &kp N0       &none              &kp ENTER &none                &none   &kp F                        &none      &kp LA(RIGHT)          &kp LC(RIGHT)     &sk LA(LCTRL)     &sk LC(LGUI)      &sk LG(LALT)      &sk LA(LC(LGUI)) 
        &none    &kp COMMA    &kp N3       &kp N2       &kp N1       &kp DOT               &none     &none     &none  &none         &none   &none      &none      &none             &sk LG(LA(LC(LSHFT)))  &sk LA(LC(LSHFT)) &sk LA(LSHFT)     &sk LC(LSHFT)     &sk LG(LSHFT)     &skq RSHFT
        &none    &none        &none        &none        &none                              &kp SPACE &kp BSPC  &kp DEL              &none   &none      &none                                               &none             &skq LALT         &skq LCTRL        &skq LGUI         &none
      >;
    };

 arrowA_layer {
      bindings = <
        &none            &none        &none             &none             &none             &none              &none                                                                                   &none      &none        &none            &none        &none         &none        &kp LC(BSPC)
        &kp ESC          &to 0        &sk LA(LG(LSHFT)) &sk LC(LG(LSHFT)) &none             &none              &none                                                                                   &none      &kp LA(HOME) &kp LA(LEFT)     &kp UP       &kp LA(RIGHT) &kp LC(END)  &kp LC(DEL)
        &sk LA(LC(LGUI)) &sk LG(LALT) &sk LC(LGUI)      &sk LA(LCTRL)     &kp LA(RIGHT)     &kp LC(RIGHT)      &none                     &none         &none                      &none   &kp G        &none      &kp HOME     &kp LEFT         &kp DOWN     &kp RIGHT     &kp END      &kp PG_UP
        &skq LSHFT      &sk LG(LSHFT) &sk LC(LSHFT)     &sk LA(LSHFT)     &sk LA(LC(LSHFT)) &sk LG(LA(LC(LSHFT)))             &none      &none         &none  &none       &none   &none   &none  &none            &kp LC(HOME) &kp LC(LEFT)     &none        &kp LC(RIGHT) &kp LC(END)  &kp PG_DN
        &none            &skq LGUI    &skq LCTRL        &skq LALT         &kp N7                                              &skq LSHFT &sk LA(LCTRL) &none              &none   &kp DEL &kp BSPC                             &none            &none        &none         &none        &none
      >;
    };

// L0 base space and enter keys
// addd ","

    space1_layer {
      bindings = <
        &none &none        &none        &none        &none        &none        &none                                                                              &none      &none        &none        &none        &none        &none        &kp LC(BSPC)
        &none &none        &none        &kp UP      &t3_alt_arrow &none        &none                                                                              &none      &none        &none        &none        &none        &none        &kp LC(DEL)
        &none &none        &kp LEFT     &kp DOWN     &kp LC(RIGHT) &kp LA(RIGHT) &none           &none  &none                        &none   &kp H                &none      &none        &none        &none        &none        &m_to0_colon &none 
        &none &none        &none        &none        &kp BSPC     &kp DEL                &none   &none  &none  &none         &none   &none   &none  &none                    &none        &none        &m_to0_comma &none        &none        &none
        &none &none        &none        &none        &none                               &none   &none  &none                        &none   &none  &kp LC(ENTER)                         &none        &none        &none        &none        &none
      >;
    };

    enter1_layer {
      bindings = <
        &none &none        &none        &none        &none        &none        &none                                                                              &none      &none        &none        &none        &none        &none        &none
        &none &none        &none        &none        &none        &none        &none                                                                              &none      &none        &none        &none        &none        &none        &none
        &none &none        &none        &none        &none        &none        &none             &none  &none                        &none   &kp I                &none      &kp LA(RIGHT) &kp LC(RIGHT) &none      &none        &none        &none
        &none &none        &none        &none        &none        &none                  &none   &none  &none  &none         &none   &none   &none  &none                    &none        &none        &none        &none        &none        &none
        &none &none        &none        &none        &none                            &kp SPACE   &none  &none                        &none   &none  &none                                 &none        &none        &none        &none        &none
      >;
    };

   space2_num_char_layer {
      bindings = <
        &none &none        &none        &none        &none        &none        &none                                                                              &none      &none        &none        &none        &none        &none        &kp LC(BSPC)
        &none &none        &none        &kp UP       &none        &none        &none                                                                              &none      &none        &none        &none        &none        &none        &kp LC(DEL)
        &none &none        &none        &none        &none        &none        &none             &none  &none                        &none   &kp K                &none      &none        &none        &none        &none        &m_to0_colon &none
        &none &none        &none        &none        &none        &none                  &none   &none  &none  &none         &none   &none   &none  &none                    &none        &none        &none        &none        &none        &none
        &none &none        &none        &none        &none                               &none   &none  &none                        &none   &none  &m_char_n_ENTER                       &none        &none        &none        &none        &none
      >;
    };
 
 //this layer doesn't work with the macros 
// doesn't work with the "swapper"/tri-state sequences that use sk an sl behaviours
  charsA_m_layer {
      bindings = <
        &none            &none             &none             &none             &none             &none        &none                                                                               &kp CARET &kp PERCENT &kp LEFT_BRACE   &kp STAR          &kp AMPERSAND    &kp RIGHT_BRACE &kp BSPC
        &none            &to 0             &sk LA(LG(LSHFT)) &sk LC(LG(LSHFT)) &none             &none        &none                                                                               &none     &kp AT      &kp LEFT_BRACKET &kp MINUS         &kp EQUAL        &kp EXCL        &kp GRAVE
        &sk LA(LC(LGUI)) &sk LG(LALT)      &m_charA4         &t3_mod5          &kp LA(RIGHT)     &kp LC(RIGHT) &kp LC(ENTER)     &kp O  &none                        &none   &kp O                &none     &kp DOLLAR  &kp LPAR         &kp SLASH         &kp PLUS         &kp SEMI        &kp SINGLE_QUOTE
        &m_charA_shift   &m_charA3         &m_charA2         &t3_mod3          &sk LA(LC(LSHFT)) &sk LG(LA(LC(LSHFT)))   &none   &none  &none  &none         &none   &none   &none     &none                &kp PIPE    &kp HASH         &kp LESS_THAN     &kp GREATER_THAN &kp QMARK       &none
        &none            &m_charA_gui      &m_charA_ctrl     &t3_mod4          &none                                     &none   &none  &none                        &kp DEL &kp BSPC &kp SPACE                         &kp RPAR         &kp RIGHT_BRACKET &none            &kp TILDE       &kp BACKSLASH
      >;
    };

  charsA_layer {
      bindings = <
        &none            &none             &none             &none             &none             &none        &none                                                                               &kp CARET &kp PERCENT &kp LEFT_BRACE   &kp STAR          &kp AMPERSAND    &kp RIGHT_BRACE &kp BSPC
        &none            &to 0             &sk LA(LG(LSHFT)) &sk LC(LG(LSHFT)) &t3_alt_arrow     &none        &none                                                                               &none     &kp AT      &kp LEFT_BRACKET &kp MINUS         &kp EQUAL        &kp EXCL        &kp GRAVE
        &sk LA(LC(LGUI)) &sk LG(LALT)      &sk LC(LGUI)      &sk LA(LCTRL)     &kp LA(RIGHT)     &kp LC(RIGHT) &kp LC(ENTER)     &kp P  &none                        &none   &kp P                &none     &kp DOLLAR  &kp LPAR         &kp SLASH         &kp PLUS         &kp SEMI        &kp SINGLE_QUOTE
        &skq LSHFT       &sk LG(LSHFT)     &sk LC(LSHFT)     &sk LA(LSHFT)     &sk LA(LC(LSHFT)) &sk LG(LA(LC(LSHFT)))   &none   &none  &none  &none         &none   &none   &none     &none                &kp PIPE    &kp HASH         &kp LESS_THAN     &kp GREATER_THAN &kp QMARK       &none
        &none            &skq LGUI         &skq LCTRL        &skq LALT         &none                                     &none   &none  &none                        &kp DEL &kp BSPC &kp SPACE                         &kp RPAR         &kp RIGHT_BRACKET &none            &kp TILDE       &kp BACKSLASH
      >;
    };  

  letters_capital_layer {
      bindings = <
        &none &none        &none        &none        &none        &none        &none                                                                              &none      &none        &none        &none         &none        &none           &none
        &none &kp LS(Q)    &kp LS(W)    &kp LS(E)    &kp LS(R)    &kp LS(T)    &none                                                                              &none      &kp LS(Y)    &kp LS(U)    &kp LS(I)     &kp LS(O)    &kp LS(P)       &none
        &none &kp LS(A)    &kp LS(S)    &kp LS(D)    &kp LS(F)    &kp LS(G)    &none               &none       &none                        &none   &kp J         &none      &kp LS(H)    &kp LS(J)    &kp LS(K)     &kp LS(L)    &kp LS(COLON)   &none
        &none &kp LS(Z)    &kp LS(X)    &kp LS(C)    &kp LS(V)    &kp LS(B)             &none      &none       &none  &none         &none   &none   &none  &none             &kp LS(N)    &kp LS(M)    &kp LS(COMMA) &kp LS(DOT)  &kp LS(UNDER)   &none
        &none &none        &none        &none        &none                              &none      &none       &none                &none   &none   &none                                 &none        &none         &none        &none           &none
      >;
    };

  letters_layer {
      bindings = <
        &none &to 0    &none    &none    &none    &none    &none                                                                                        &none      &none    &none    &none     &none    &none       &none
        &none &kp Q    &kp W    &kp E    &kp R    &kp T    &none                                                                                        &none      &kp Y    &kp U    &kp I     &kp O    &kp P       &none
        &none &kp A    &kp S    &kp D    &kp F    &kp G    &none                  &none       &none                        &none   &kp L                &none      &kp H    &kp J    &kp K     &kp L    &kp COLON   &none
        &none &kp Z    &kp X    &kp C    &kp V    &kp B                &none      &none       &none  &none         &none   &none   &none  &none                    &kp N    &kp M    &kp COMMA &kp DOT  &kp UNDER   &none
        &none &none    &none    &none    &none                         &none      &none       &none                        &none   &none  &none                             &none    &none     &none    &none       &none  
      >;
    };

  f1_layer {
      bindings = <
        &none    &none  &kp PAUSE_BREAK &kp PSCRN  &kp KP_NUM  &kp SYSREQ &none                                                                                        &none      &none                  &none             &none             &none             &none             &none
&kp SCROLLLOCK   &to 0  &kp F9          &kp F8     &kp F7      &kp F12    &none                                                                                        &none      &none                  &none             &sk LC(LG(LSHFT)) &sk LA(LG(LSHFT)) &sk LA(LC(LSHFT)) &none
        &kp INS  &to 0  &kp F6          &kp F5     &kp F4      &kp F10    &none                &none       &none                        &none   &kp Y                  &none      &kp LA(RIGHT)          &kp LC(RIGHT)     &sk LA(LCTRL)     &sk LC(LGUI)      &sk LG(LALT)      &sk LA(LC(LGUI))
        &kp CAPS &kp Z  &kp F3          &kp F2     &kp F1      &kp F11            &none        &none       &none  &none         &none   &none   &none  &none                      &sk LG(LA(LC(LSHFT)))  &sk LA(LC(LSHFT)) &sk LA(LSHFT)     &sk LC(LSHFT)     &sk LG(LSHFT)     &skq RSHFT
        &none    &none  &none           &none      &none                          &none        &none       &none                        &none   &none  &none                                             &none             &skq LALT         &skq LCTRL        &skq LGUI         &none
      >;
    };

// when on layer 0 it allows you to type:
// mod+leter, mod+leter
// mod+number
// mod+numer, mod+number

  base_mod_layer {
      bindings = <
       &kp  EQUAL   &td_n1     &td_n2     &td_n3    &td_n4    &td_n5  &none                                                                                           &none    &td_n6     &td_n7      &td_n8      &td_n9      &td_n0      &kp BSPC
       &kp  ESC     &kp Q      &kp W      &kp E     &kp R     &kp T   &none                                                                                           &none    &kp Y      &kp  U      &kp I       &kp O       &kp P       &kp DEL
       &kp  TAB     &kp A      &kp S      &kp D     &kp F     &kp G   &kp LC(RIGHT)             &kp ENTER  &none                       &none  &kp Q                   &none    &kp H      &kp  J      &kp K       &kp L       &kp COLON   &kp DOUBLE_QUOTES
       &kp A        &kp Z      &kp X      &kp C     &kp V     &kp B                    &none    &none      &kp BSPC  &none      &none  &none  &none  &none                     &kp N      &kp  M      &kp COMMA   &kp DOT     &kp UNDER   &kp B
       &none        &none     &none     &none    &none                             &kp SPACE     &none     &kp DEL                     &none  &none  &kp ENTER                             &none      &none      &none      &none      &none
      >;
    };

// TODO: ARROW_MODS
// used on the arrowB  layer to move between tabs up/down 
//  { "keys": ["ctrl+1"], "command": "focus_group", "args": { "group": 0 } },

  arrowb_ctrl_l {
      bindings = <
        &none &none    &none        &none        &none        &none        &none                                                                                    &none      &none   &none    &none    &none   &none   &none
        &none &to 0    &kp LC(N9)   &kp LC(N8)   &kp LC(N7)   &none        &none                                                                                    &none      &none   &none    &none    &none   &none   &none
        &none &to 0    &kp LC(N6)   &kp LC(N5)   &kp LC(N4)   &kp LC(N0)   &none                       &none  &none                        &none   &kp V            &none      &none   &none    &none    &none   &none   &none
        &none &none    &kp LC(N3)   &kp LC(N2)   &kp LC(N1)   &none                            &none   &none  &none  &none         &none   &none   &none  &none                &none   &none    &none    &none   &none   &none
        &none &none    &none        &none        &none                                        &none    &none  &none                        &none   &none  &none                        &none    &none    &none   &none   &none
      >;
    };  


  };
};



// W next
